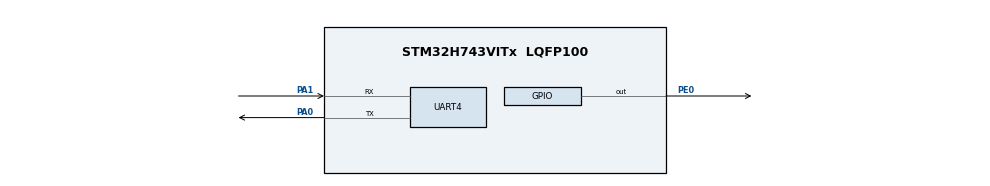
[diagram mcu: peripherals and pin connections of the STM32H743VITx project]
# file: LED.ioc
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CORTEX_M7.CPU_DCache=Disabled
CORTEX_M7.CPU_ICache=Disabled
FREERTOS.Tasks01=Task_LED0,0,128,Func_LED0,Default,NULL,Dynamic,NULL,NULL;TASK_LED1,-3,128,Func_LED1,Default,NULL,Dynamic,NULL,NULL
Mcu.Family=STM32H7
Mcu.Name=STM32H743VITx
Mcu.Package=LQFP100
NVIC.PriorityGroup=NVIC_PRIORITYGROUP_4
NVIC.TIM3_IRQn=true\:5\:0\:false\:false\:true\:true\:true\:true
NVIC.TIM4_IRQn=true\:0\:0\:false\:false\:true\:false\:false\:true
NVIC.TimeBase=TIM4_IRQn
NVIC.TimeBaseIP=TIM4
PA0.Mode=Asynchronous
PA0.Signal=UART4_TX
PA1.Mode=Asynchronous
PA1.Signal=UART4_RX
PE0.Signal=GPIO_Output
PH0-OSC_IN\ (PH0).Mode=HSE-External-Oscillator
PH0-OSC_IN\ (PH0).Signal=RCC_OSC_IN
PH1-OSC_OUT\ (PH1).Mode=HSE-External-Oscillator
PH1-OSC_OUT\ (PH1).Signal=RCC_OSC_OUT
ProjectManager.HeapSize=0x200
ProjectManager.StackSize=0x400
ProjectManager.TargetToolchain=MDK-ARM V5
RCC.ADCFreq_Value=76000000
RCC.APB1Freq_Value=100000000
RCC.APB2Freq_Value=100000000
RCC.APB3Freq_Value=100000000
RCC.APB4Freq_Value=100000000
RCC.CortexFreq_Value=400000000
RCC.D1PPRE=RCC_APB3_DIV2
RCC.D2PPRE1=RCC_APB1_DIV2
RCC.D2PPRE2=RCC_APB2_DIV2
RCC.D3PPRE=RCC_APB4_DIV2
RCC.DIVM1=1
RCC.DIVM2=1
RCC.DIVN1=100
RCC.DIVN2=19
RCC.HCLKFreq_Value=200000000
RCC.HPRE=RCC_HCLK_DIV2
RCC.HSE_VALUE=8000000
RCC.PLLSourceVirtual=RCC_PLLSOURCE_HSE
RCC.PWR_Regulator_Voltage_Scale=PWR_REGULATOR_VOLTAGE_SCALE1
RCC.SYSCLKFreq_VALUE=400000000
RCC.SYSCLKSource=RCC_SYSCLKSOURCE_PLLCLK
RCC.USBFreq_Value=400000000
TIM3.Period=1000-1
TIM3.Prescaler=100-1
TIM3.TIM_MasterOutputTrigger=TIM_TRGO_UPDATE
TIM3.TIM_MasterSlaveMode=TIM_MASTERSLAVEMODE_DISABLE
VP_FREERTOS_VS_CMSIS_V1.Mode=CMSIS_V1
VP_SYS_VS_tim4.Mode=TIM4
VP_TIM3_VS_ClockSourceINT.Mode=Internal
board=custom

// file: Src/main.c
/* USER CODE BEGIN Header */
/**
  ******************************************************************************
  * @file           : main.c
  * @brief          : Main program body
  ******************************************************************************
  * @attention
  *
  * <h2><center>&copy; Copyright (c) 2019 STMicroelectronics.
  * All rights reserved.</center></h2>
  *
  * This software component is licensed by ST under Ultimate Liberty license
  * SLA0044, the "License"; You may not use this file except in compliance with
  * the License. You may obtain a copy of the License at:
  *                             www.st.com/SLA0044
  *
  ******************************************************************************
  */
/* USER CODE END Header */

#include "main.h"
#include "cmsis_os.h"
#include "tim.h"
#include "usart.h"
#include "gpio.h"

void SystemClock_Config(void);
void MX_FREERTOS_Init(void);

int main(void)
{

  /* MCU Configuration--------------------------------------------------------*/

  /* Reset of all peripherals, Initializes the Flash interface and the Systick. */
  HAL_Init();

  /* Configure the system clock */
  SystemClock_Config();

  /* Initialize all configured peripherals */
  MX_GPIO_Init();
  MX_TIM3_Init();
  MX_UART4_Init();

  /* Call init function for freertos objects (in freertos.c) */
  MX_FREERTOS_Init();

  /* Start scheduler */
  osKernelStart();

  /* We should never get here as control is now taken by the scheduler */

  /* Infinite loop */
  while (1)
  {
	printf("freertos wrong");
  }
}

void SystemClock_Config(void)
{
  RCC_OscInitTypeDef RCC_OscInitStruct = {0};
  RCC_ClkInitTypeDef RCC_ClkInitStruct = {0};
  RCC_PeriphCLKInitTypeDef PeriphClkInitStruct = {0};

  /** Supply configuration update enable
  */
  HAL_PWREx_ConfigSupply(PWR_LDO_SUPPLY);
  /** Configure the main internal regulator output voltage
  */
  __HAL_PWR_VOLTAGESCALING_CONFIG(PWR_REGULATOR_VOLTAGE_SCALE1);

  while(!__HAL_PWR_GET_FLAG(PWR_FLAG_VOSRDY)) {}
  /** Initializes the CPU, AHB and APB busses clocks
  */
  RCC_OscInitStruct.OscillatorType = RCC_OSCILLATORTYPE_HSE;
  RCC_OscInitStruct.HSEState = RCC_HSE_ON;
  RCC_OscInitStruct.PLL.PLLState = RCC_PLL_ON;
  RCC_OscInitStruct.PLL.PLLSource = RCC_PLLSOURCE_HSE;
  RCC_OscInitStruct.PLL.PLLM = 1;
  RCC_OscInitStruct.PLL.PLLN = 100;
  RCC_OscInitStruct.PLL.PLLP = 2;
  RCC_OscInitStruct.PLL.PLLQ = 2;
  RCC_OscInitStruct.PLL.PLLR = 2;
  RCC_OscInitStruct.PLL.PLLRGE = RCC_PLL1VCIRANGE_3;
  RCC_OscInitStruct.PLL.PLLVCOSEL = RCC_PLL1VCOWIDE;
  RCC_OscInitStruct.PLL.PLLFRACN = 0;
  if (HAL_RCC_OscConfig(&RCC_OscInitStruct) != HAL_OK)
  {
    Error_Handler();
  }
  /** Initializes the CPU, AHB and APB busses clocks
  */
  RCC_ClkInitStruct.ClockType = RCC_CLOCKTYPE_HCLK|RCC_CLOCKTYPE_SYSCLK
                              |RCC_CLOCKTYPE_PCLK1|RCC_CLOCKTYPE_PCLK2
                              |RCC_CLOCKTYPE_D3PCLK1|RCC_CLOCKTYPE_D1PCLK1;
  RCC_ClkInitStruct.SYSCLKSource = RCC_SYSCLKSOURCE_PLLCLK;
  RCC_ClkInitStruct.SYSCLKDivider = RCC_SYSCLK_DIV1;
  RCC_ClkInitStruct.AHBCLKDivider = RCC_HCLK_DIV2;
  RCC_ClkInitStruct.APB3CLKDivider = RCC_APB3_DIV2;
  RCC_ClkInitStruct.APB1CLKDivider = RCC_APB1_DIV2;
  RCC_ClkInitStruct.APB2CLKDivider = RCC_APB2_DIV2;
  RCC_ClkInitStruct.APB4CLKDivider = RCC_APB4_DIV2;

  if (HAL_RCC_ClockConfig(&RCC_ClkInitStruct, FLASH_LATENCY_2) != HAL_OK)
  {
    Error_Handler();
  }
  PeriphClkInitStruct.PeriphClockSelection = RCC_PERIPHCLK_UART4;
  PeriphClkInitStruct.Usart234578ClockSelection = RCC_USART234578CLKSOURCE_D2PCLK1;
  if (HAL_RCCEx_PeriphCLKConfig(&PeriphClkInitStruct) != HAL_OK)
  {
    Error_Handler();
  }
}

void HAL_TIM_PeriodElapsedCallback(TIM_HandleTypeDef *htim)
{
  if (htim->Instance == TIM4) {
    HAL_IncTick();
  }
}

void Error_Handler(void)
{
}

/************************ (C) COPYRIGHT STMicroelectronics *****END OF FILE****/

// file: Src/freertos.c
/* USER CODE BEGIN Header */
/**
  ******************************************************************************
  * File Name          : freertos.c
  * Description        : Code for freertos applications
  ******************************************************************************
  * @attention
  *
  * <h2><center>&copy; Copyright (c) 2019 STMicroelectronics.
  * All rights reserved.</center></h2>
  *
  * This software component is licensed by ST under Ultimate Liberty license
  * SLA0044, the "License"; You may not use this file except in compliance with
  * the License. You may obtain a copy of the License at:
  *                             www.st.com/SLA0044
  *
  ******************************************************************************
  */
/* USER CODE END Header */

#include "FreeRTOS.h"
#include "task.h"
#include "main.h"
#include "cmsis_os.h"

osThreadId Task_LED0Handle;
osThreadId TASK_LED1Handle;

void Func_LED0(void const * argument);
void Func_LED1(void const * argument);

void MX_FREERTOS_Init(void); /* (MISRA C 2004 rule 8.1) */

void MX_FREERTOS_Init(void) {

  /* Create the thread(s) */
  /* definition and creation of Task_LED0 */
  osThreadDef(Task_LED0, Func_LED0, osPriorityNormal, 0, 128);
  Task_LED0Handle = osThreadCreate(osThread(Task_LED0), NULL);

  /* definition and creation of TASK_LED1 */
  osThreadDef(TASK_LED1, Func_LED1, osPriorityIdle, 0, 128);
  TASK_LED1Handle = osThreadCreate(osThread(TASK_LED1), NULL);

}

void Func_LED0(void const * argument)
{

  /* USER CODE BEGIN Func_LED0 */
  /* Infinite loop */
  for(;;)
  {

	printf("Task0 is running\r\n");

    osDelay(1000);
  }
  /* USER CODE END Func_LED0 */
}

void Func_LED1(void const * argument)
{
  /* USER CODE BEGIN Func_LED1 */
  /* Infinite loop */
  for(;;)
  {
	  printf("Task1 is running\r\n");

	  osDelay(1000);
  }
  /* USER CODE END Func_LED1 */
}

/************************ (C) COPYRIGHT STMicroelectronics *****END OF FILE****/
